VERSION ""

NS_ :

BS_:

BU_: VCU AMK

BO_ 3221225472 VECTOR__INDEPENDENT_SIG_MSG: 1 Vector__XXX
 SG_ Status : 8|8@1+ (1,0) [0|0] ""  VCU

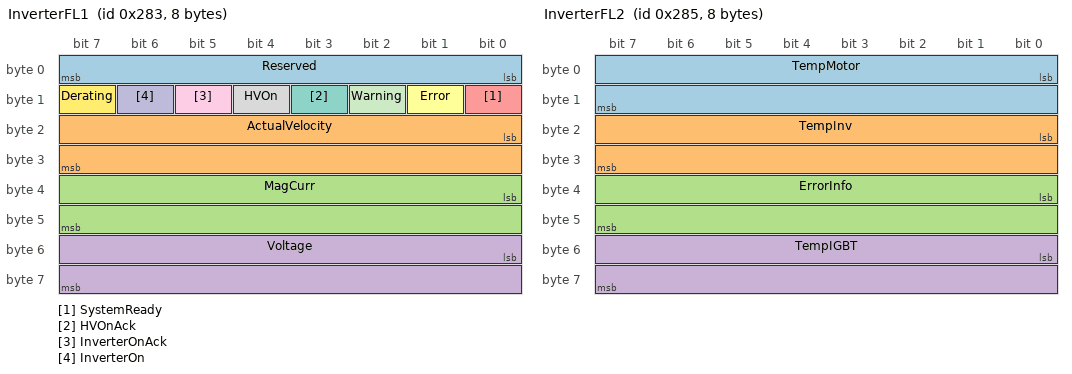
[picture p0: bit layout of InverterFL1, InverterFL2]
BO_ 643 InverterFL1: 8 AMK
 SG_ Reserved : 0|8@1+ (1,0) [0|0] ""  VCU
 SG_ ActualVelocity : 16|16@1- (1,0) [0|0] "rpm"  VCU
 SG_ MagCurr : 32|16@1- (1,0) [0|0] ""  VCU
 SG_ Voltage : 48|16@1- (1,0) [0|0] "V"  VCU
 SG_ SystemReady : 8|1@1+ (1,0) [0|0] ""  VCU
 SG_ Error : 9|1@1+ (1,0) [0|0] ""  VCU
 SG_ HVOnAck : 11|1@1+ (1,0) [0|0] ""  VCU
 SG_ HVOn : 12|1@1+ (1,0) [0|0] ""  VCU
 SG_ InverterOnAck : 13|1@1+ (1,0) [0|0] ""  VCU
 SG_ InverterOn : 14|1@1+ (1,0) [0|0] ""  VCU
 SG_ Warning : 10|1@1+ (1,0) [0|0] ""  VCU
 SG_ Derating : 15|1@1+ (1,0) [0|0] ""  VCU

BO_ 645 InverterFL2: 8 AMK
 SG_ TempMotor : 0|16@1- (0.1,0) [0|0] "C"  VCU
 SG_ TempInv : 16|16@1- (0.1,0) [0|0] "C"  VCU
 SG_ ErrorInfo : 32|16@1+ (1,0) [0|0] ""  VCU
 SG_ TempIGBT : 48|16@1- (0.1,0) [0|0] "C"  VCU

BO_ 388 VCUInvFL: 8 VCU
 SG_ AMK_bReserved : 0|8@1+ (1,0) [0|0] ""  AMK
 SG_ AMK_bInverterOn : 9|1@1+ (1,0) [0|0] "" AMK
 SG_ AMK_bDcOn : 10|1@1+ (1,0) [0|0] "" AMK
 SG_ AMK_bEnable : 11|1@1+ (1,0) [0|0] "" AMK
 SG_ AMK_bErrorReset : 12|1@1+ (1,0) [0|0] "" AMK
 SG_ AMK_bReservedEnd : 13|4@1+ (1,0) [0|0] "" AMK
 SG_ TargetVel : 16|16@1- (1,0) [0|0] "rpm"  AMK
 SG_ PosTorq : 32|16@1- (0.0098,0) [0|0] "Nm"  AMK
 SG_ NegTorq : 48|16@1- (0.0098,0) [0|0] "Nm"  AMK

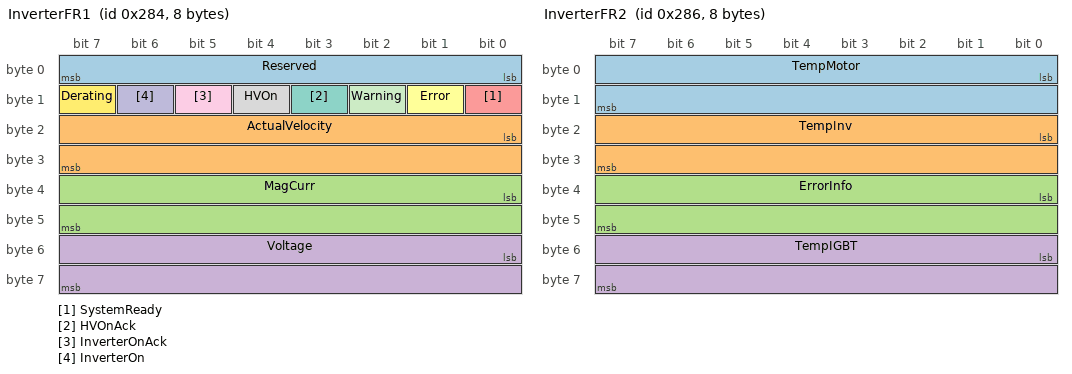
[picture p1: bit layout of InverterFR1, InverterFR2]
BO_ 644 InverterFR1: 8 AMK
 SG_ Reserved : 0|8@1+ (1,0) [0|0] ""  VCU
 SG_ ActualVelocity : 16|16@1- (1,0) [0|0] "rpm"  VCU
 SG_ MagCurr : 32|16@1- (1,0) [0|0] ""  VCU
 SG_ Voltage : 48|16@1- (1,0) [0|0] "V"  VCU
 SG_ SystemReady : 8|1@1+ (1,0) [0|0] ""  VCU
 SG_ Error : 9|1@1+ (1,0) [0|0] ""  VCU
 SG_ HVOnAck : 11|1@1+ (1,0) [0|0] ""  VCU
 SG_ HVOn : 12|1@1+ (1,0) [0|0] ""  VCU
 SG_ InverterOnAck : 13|1@1+ (1,0) [0|0] ""  VCU
 SG_ InverterOn : 14|1@1+ (1,0) [0|0] ""  VCU
 SG_ Warning : 10|1@1+ (1,0) [0|0] ""  VCU
 SG_ Derating : 15|1@1+ (1,0) [0|0] ""  VCU

BO_ 646 InverterFR2: 8 AMK
 SG_ TempMotor : 0|16@1- (0.1,0) [0|0] "C"  VCU
 SG_ TempInv : 16|16@1- (0.1,0) [0|0] "C"  VCU
 SG_ ErrorInfo : 32|16@1+ (1,0) [0|0] ""  VCU
 SG_ TempIGBT : 48|16@1- (0.1,0) [0|0] "C"  VCU

BO_ 389 VCUInvFR: 8 VCU
 SG_ AMK_bReserved : 0|8@1+ (1,0) [0|0] ""  AMK
 SG_ AMK_bInverterOn : 9|1@1+ (1,0) [0|0] "" AMK
 SG_ AMK_bDcOn : 10|1@1+ (1,0) [0|0] "" AMK
 SG_ AMK_bEnable : 11|1@1+ (1,0) [0|0] "" AMK
 SG_ AMK_bErrorReset : 12|1@1+ (1,0) [0|0] "" AMK
 SG_ AMK_bReservedEnd : 13|4@1+ (1,0) [0|0] "" AMK
 SG_ TargetVel : 16|16@1- (1,0) [0|0] "rpm"  AMK
 SG_ PosTorq : 32|16@1- (0.0098,0) [0|0] "Nm"  AMK
 SG_ NegTorq : 48|16@1- (0.0098,0) [0|0] "Nm"  AMK

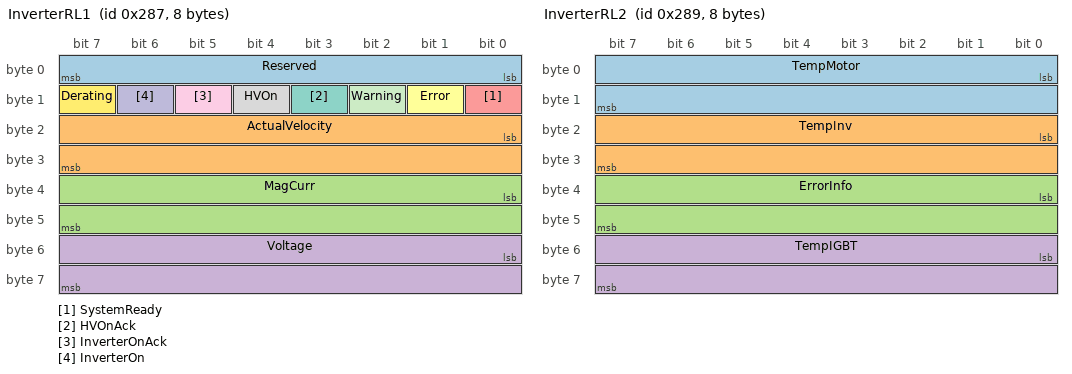
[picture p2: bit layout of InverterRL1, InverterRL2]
BO_ 647 InverterRL1: 8 AMK
 SG_ Reserved : 0|8@1+ (1,0) [0|0] ""  VCU
 SG_ ActualVelocity : 16|16@1- (1,0) [0|0] "rpm"  VCU
 SG_ MagCurr : 32|16@1- (1,0) [0|0] ""  VCU
 SG_ Voltage : 48|16@1- (1,0) [0|0] "V"  VCU
 SG_ SystemReady : 8|1@1+ (1,0) [0|0] ""  VCU
 SG_ Error : 9|1@1+ (1,0) [0|0] ""  VCU
 SG_ HVOnAck : 11|1@1+ (1,0) [0|0] ""  VCU
 SG_ HVOn : 12|1@1+ (1,0) [0|0] ""  VCU
 SG_ InverterOnAck : 13|1@1+ (1,0) [0|0] ""  VCU
 SG_ InverterOn : 14|1@1+ (1,0) [0|0] ""  VCU
 SG_ Warning : 10|1@1+ (1,0) [0|0] ""  VCU
 SG_ Derating : 15|1@1+ (1,0) [0|0] ""  VCU

BO_ 649 InverterRL2: 8 AMK
 SG_ TempMotor : 0|16@1- (0.1,0) [0|0] "C"  VCU
 SG_ TempInv : 16|16@1- (0.1,0) [0|0] "C"  VCU
 SG_ ErrorInfo : 32|16@1+ (1,0) [0|0] ""  VCU
 SG_ TempIGBT : 48|16@1- (0.1,0) [0|0] "C"  VCU

BO_ 392 VCUInvRL: 8 VCU
 SG_ AMK_bReserved : 0|8@1+ (1,0) [0|0] ""  AMK
 SG_ AMK_bInverterOn : 9|1@1+ (1,0) [0|0] "" AMK
 SG_ AMK_bDcOn : 10|1@1+ (1,0) [0|0] "" AMK
 SG_ AMK_bEnable : 11|1@1+ (1,0) [0|0] "" AMK
 SG_ AMK_bErrorReset : 12|1@1+ (1,0) [0|0] "" AMK
 SG_ AMK_bReservedEnd : 13|4@1+ (1,0) [0|0] "" AMK
 SG_ TargetVel : 16|16@1- (1,0) [0|0] "rpm"  AMK
 SG_ PosTorq : 32|16@1- (0.0098,0) [0|0] "Nm"  AMK
 SG_ NegTorq : 48|16@1- (0.0098,0) [0|0] "Nm"  AMK

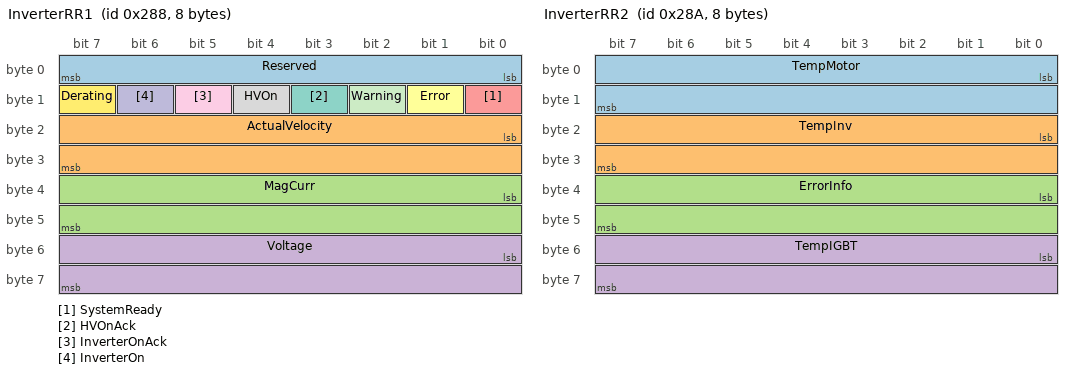
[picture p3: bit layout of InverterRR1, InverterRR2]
BO_ 648 InverterRR1: 8 AMK
 SG_ Reserved : 0|8@1+ (1,0) [0|0] ""  VCU
 SG_ ActualVelocity : 16|16@1- (1,0) [0|0] "rpm"  VCU
 SG_ MagCurr : 32|16@1- (1,0) [0|0] ""  VCU
 SG_ Voltage : 48|16@1- (1,0) [0|0] "V"  VCU
 SG_ SystemReady : 8|1@1+ (1,0) [0|0] ""  VCU
 SG_ Error : 9|1@1+ (1,0) [0|0] ""  VCU
 SG_ HVOnAck : 11|1@1+ (1,0) [0|0] ""  VCU
 SG_ HVOn : 12|1@1+ (1,0) [0|0] ""  VCU
 SG_ InverterOnAck : 13|1@1+ (1,0) [0|0] ""  VCU
 SG_ InverterOn : 14|1@1+ (1,0) [0|0] ""  VCU
 SG_ Warning : 10|1@1+ (1,0) [0|0] ""  VCU
 SG_ Derating : 15|1@1+ (1,0) [0|0] ""  VCU

BO_ 650 InverterRR2: 8 AMK
 SG_ TempMotor : 0|16@1- (0.1,0) [0|0] "C"  VCU
 SG_ TempInv : 16|16@1- (0.1,0) [0|0] "C"  VCU
 SG_ ErrorInfo : 32|16@1+ (1,0) [0|0] ""  VCU
 SG_ TempIGBT : 48|16@1- (0.1,0) [0|0] "C"  VCU

BO_ 393 VCUInvRR: 8 VCU
 SG_ AMK_bReserved : 0|8@1+ (1,0) [0|0] ""  AMK
 SG_ AMK_bInverterOn : 9|1@1+ (1,0) [0|0] "" AMK
 SG_ AMK_bDcOn : 10|1@1+ (1,0) [0|0] "" AMK
 SG_ AMK_bEnable : 11|1@1+ (1,0) [0|0] "" AMK
 SG_ AMK_bErrorReset : 12|1@1+ (1,0) [0|0] "" AMK
 SG_ AMK_bReservedEnd : 13|4@1+ (1,0) [0|0] "" AMK
 SG_ TargetVel : 16|16@1- (1,0) [0|0] "rpm"  AMK
 SG_ PosTorq : 32|16@1- (0.0098,0) [0|0] "Nm"  AMK
 SG_ NegTorq : 48|16@1- (0.0098,0) [0|0] "Nm"  AMK
